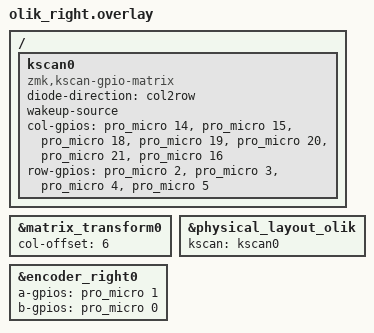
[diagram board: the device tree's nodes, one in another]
#include "olik.dtsi"

/ {
	kscan0: kscan0 {
		compatible = "zmk,kscan-gpio-matrix";
		diode-direction = "col2row";
		wakeup-source;
		
		
		col-gpios
		= <&pro_micro 14 GPIO_ACTIVE_HIGH>
		, <&pro_micro 15 GPIO_ACTIVE_HIGH>
		, <&pro_micro 18 GPIO_ACTIVE_HIGH>
		, <&pro_micro 19 GPIO_ACTIVE_HIGH>
		, <&pro_micro 20 GPIO_ACTIVE_HIGH>
		, <&pro_micro 21 GPIO_ACTIVE_HIGH>
		, <&pro_micro 16 GPIO_ACTIVE_HIGH>
		;
		
		row-gpios
		= <&pro_micro 2 (GPIO_ACTIVE_HIGH | GPIO_PULL_DOWN)>
		, <&pro_micro 3 (GPIO_ACTIVE_HIGH | GPIO_PULL_DOWN)>
		, <&pro_micro 4 (GPIO_ACTIVE_HIGH | GPIO_PULL_DOWN)>
		, <&pro_micro 5 (GPIO_ACTIVE_HIGH | GPIO_PULL_DOWN)>
		;
	};
};

&matrix_transform0 {
	col-offset = <6>;
};

&physical_layout_olik {
	kscan = <&kscan0>;
};

&encoder_right0 {
	a-gpios = <&pro_micro 1 (GPIO_ACTIVE_HIGH | GPIO_PULL_UP)>;
	b-gpios = <&pro_micro 0 (GPIO_ACTIVE_HIGH | GPIO_PULL_UP)>;
	status = "okay";
};

